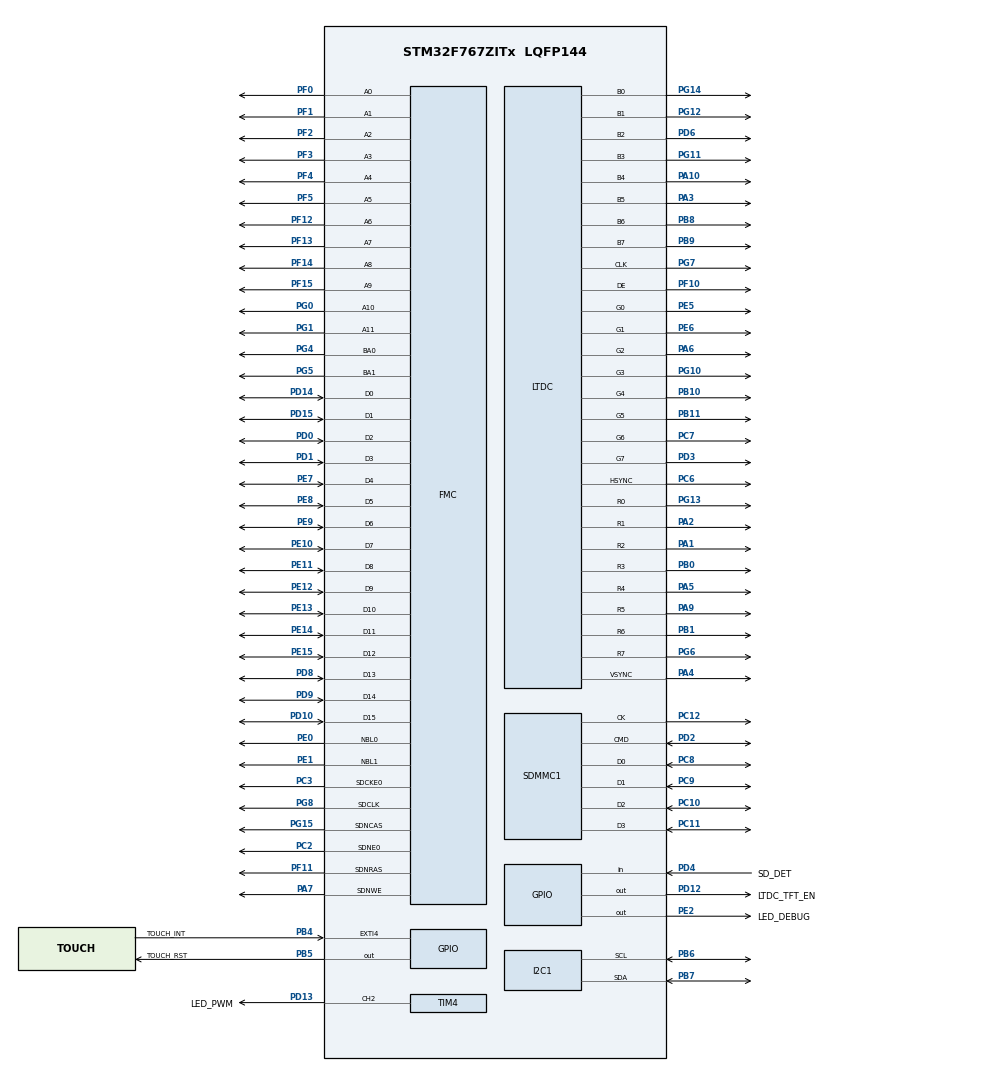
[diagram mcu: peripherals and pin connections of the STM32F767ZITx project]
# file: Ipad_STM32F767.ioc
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CORTEX_M7.CPU_DCache=Enabled
CORTEX_M7.CPU_ICache=Enabled
CORTEX_M7.Cortex_Memory_Protection_Unit_Region1_Settings_S-AccessPermission_S=MPU_REGION_FULL_ACCESS
CORTEX_M7.Cortex_Memory_Protection_Unit_Region1_Settings_S-BaseAddress_S=0xC0000000
CORTEX_M7.Cortex_Memory_Protection_Unit_Region1_Settings_S-DisableExec_S=MPU_INSTRUCTION_ACCESS_DISABLE
CORTEX_M7.Cortex_Memory_Protection_Unit_Region1_Settings_S-Enable_S=MPU_REGION_ENABLE
CORTEX_M7.Cortex_Memory_Protection_Unit_Region1_Settings_S-IsBufferable_S=MPU_ACCESS_BUFFERABLE
CORTEX_M7.Cortex_Memory_Protection_Unit_Region1_Settings_S-IsCacheable_S=MPU_ACCESS_CACHEABLE
CORTEX_M7.Cortex_Memory_Protection_Unit_Region1_Settings_S-IsShareable_S=MPU_ACCESS_NOT_SHAREABLE
CORTEX_M7.Cortex_Memory_Protection_Unit_Region1_Settings_S-Number_Spec=MPU_REGION_NUMBER1
CORTEX_M7.Cortex_Memory_Protection_Unit_Region1_Settings_S-Size_S=MPU_REGION_SIZE_8MB
CORTEX_M7.Cortex_Memory_Protection_Unit_Region1_Settings_S-SubRegionDisable_S=0x0
CORTEX_M7.Cortex_Memory_Protection_Unit_Region1_Settings_S-TypeExtField_S=MPU_TEX_LEVEL1
CORTEX_M7.Cortex_Memory_Protection_Unit_Region2_Settings_S-AccessPermission_S=MPU_REGION_FULL_ACCESS
CORTEX_M7.Cortex_Memory_Protection_Unit_Region2_Settings_S-BaseAddress_S=0xA0000000
CORTEX_M7.Cortex_Memory_Protection_Unit_Region2_Settings_S-DisableExec_S=MPU_INSTRUCTION_ACCESS_DISABLE
CORTEX_M7.Cortex_Memory_Protection_Unit_Region2_Settings_S-Enable_S=MPU_REGION_ENABLE
CORTEX_M7.Cortex_Memory_Protection_Unit_Region2_Settings_S-IsBufferable_S=MPU_ACCESS_BUFFERABLE
CORTEX_M7.Cortex_Memory_Protection_Unit_Region2_Settings_S-IsCacheable_S=MPU_ACCESS_NOT_CACHEABLE
CORTEX_M7.Cortex_Memory_Protection_Unit_Region2_Settings_S-IsShareable_S=MPU_ACCESS_SHAREABLE
CORTEX_M7.Cortex_Memory_Protection_Unit_Region2_Settings_S-Number_Spec=MPU_REGION_NUMBER2
CORTEX_M7.Cortex_Memory_Protection_Unit_Region2_Settings_S-Size_S=MPU_REGION_SIZE_64KB
CORTEX_M7.Cortex_Memory_Protection_Unit_Region2_Settings_S-SubRegionDisable_S=0x0
CORTEX_M7.Cortex_Memory_Protection_Unit_Region2_Settings_S-TypeExtField_S=MPU_TEX_LEVEL0
CORTEX_M7.default_mode_Activation=1
FATFS.BSP.number=1
FATFS._USE_LFN=1
FATFS0.BSP.STBoard=false
FATFS0.BSP.api=Unknown
FATFS0.BSP.instance=PD4
FATFS0.BSP.ip=GPIO
FATFS0.BSP.mode=Input
FATFS0.BSP.name=Detect_SDIO
FATFS0.BSP.solution=PD4
FMC.CASLatency1=FMC_SDRAM_CAS_LATENCY_3
FMC.ColumnBitsNumber1=FMC_SDRAM_COLUMN_BITS_NUM_8
FMC.ExitSelfRefreshDelay1=7
FMC.LoadToActiveDelay1=2
FMC.RCDDelay1=2
FMC.RPDelay1=2
FMC.RPDelay2=2
FMC.ReadBurst1=FMC_SDRAM_RBURST_ENABLE
FMC.ReadPipeDelay1=FMC_SDRAM_RPIPE_DELAY_1
FMC.ReadPipeDelay2=FMC_SDRAM_RPIPE_DELAY_1
FMC.RowCycleDelay1=7
FMC.RowCycleDelay2=7
FMC.SDClockPeriod1=FMC_SDRAM_CLOCK_PERIOD_2
FMC.SDClockPeriod2=FMC_SDRAM_CLOCK_PERIOD_2
FMC.SelfRefreshTime1=4
FMC.WriteRecoveryTime1=3
I2C1.Timing=0x9042161B
LTDC.ActiveH=600
LTDC.ActiveW=1024
LTDC.Alpha_L0=255
LTDC.DEPolarity=LTDC_DEPOLARITY_AL
LTDC.FBStartAdress_L0=0xC0000000
LTDC.HBP=140
LTDC.HFP=160
LTDC.HSPolarity=LTDC_HSPOLARITY_AL
LTDC.HSync=20
LTDC.ImageHeight_L0=600
LTDC.ImageWidth_L0=1024
LTDC.PixelFormat_L0=LTDC_PIXEL_FORMAT_RGB565
LTDC.VBP=20
LTDC.VFP=12
LTDC.VSPolarity=LTDC_VSPOLARITY_AL
LTDC.VSync=3
LTDC.WindowX1_L0=1024
LTDC.WindowY1_L0=600
Mcu.Family=STM32F7
Mcu.Name=STM32F767ZITx
Mcu.Package=LQFP144
NVIC.EXTI4_IRQn=true\:5\:0\:false\:false\:true\:true\:true\:true
NVIC.PriorityGroup=NVIC_PRIORITYGROUP_4
PA1.GPIO_Speed=GPIO_SPEED_FREQ_VERY_HIGH
PA1.Mode=RGB888
PA1.Signal=LTDC_R2
PA10.GPIO_Speed=GPIO_SPEED_FREQ_VERY_HIGH
PA10.Mode=RGB888
PA10.Signal=LTDC_B4
PA13.Mode=Serial_Wire
PA13.Signal=SYS_JTMS-SWDIO
PA14.Mode=Serial_Wire
PA14.Signal=SYS_JTCK-SWCLK
PA2.GPIO_Speed=GPIO_SPEED_FREQ_VERY_HIGH
PA2.Mode=RGB888
PA2.Signal=LTDC_R1
PA3.GPIO_Speed=GPIO_SPEED_FREQ_VERY_HIGH
PA3.Mode=RGB888
PA3.Signal=LTDC_B5
PA4.GPIO_Speed=GPIO_SPEED_FREQ_VERY_HIGH
PA4.Mode=RGB888
PA4.Signal=LTDC_VSYNC
PA5.GPIO_Speed=GPIO_SPEED_FREQ_VERY_HIGH
PA5.Mode=RGB888
PA5.Signal=LTDC_R4
PA6.GPIO_Speed=GPIO_SPEED_FREQ_VERY_HIGH
PA6.Mode=RGB888
PA6.Signal=LTDC_G2
PA7.Signal=FMC_SDNWE
PA9.GPIO_Speed=GPIO_SPEED_FREQ_VERY_HIGH
PA9.Mode=RGB888
PA9.Signal=LTDC_R5
PB0.GPIO_Speed=GPIO_SPEED_FREQ_VERY_HIGH
PB0.Mode=RGB888
PB0.Signal=LTDC_R3
PB1.GPIO_Speed=GPIO_SPEED_FREQ_VERY_HIGH
PB1.Mode=RGB888
PB1.Signal=LTDC_R6
PB10.GPIO_Speed=GPIO_SPEED_FREQ_VERY_HIGH
PB10.Mode=RGB888
PB10.Signal=LTDC_G4
PB11.GPIO_Speed=GPIO_SPEED_FREQ_VERY_HIGH
PB11.Mode=RGB888
PB11.Signal=LTDC_G5
PB4.GPIO_Label=TOUCH_INT
PB4.GPIO_ModeDefaultEXTI=GPIO_MODE_IT_RISING_FALLING
PB4.Signal=GPXTI4
PB5.GPIO_Label=TOUCH_RST
PB5.Signal=GPIO_Output
PB6.GPIO_PuPd=GPIO_PULLUP
PB6.GPIO_Speed=GPIO_SPEED_FREQ_VERY_HIGH
PB6.Mode=I2C
PB6.Signal=I2C1_SCL
PB7.GPIO_PuPd=GPIO_PULLUP
PB7.GPIO_Speed=GPIO_SPEED_FREQ_VERY_HIGH
PB7.Mode=I2C
PB7.Signal=I2C1_SDA
PB8.GPIO_Speed=GPIO_SPEED_FREQ_VERY_HIGH
PB8.Mode=RGB888
PB8.Signal=LTDC_B6
PB9.GPIO_Speed=GPIO_SPEED_FREQ_VERY_HIGH
PB9.Mode=RGB888
PB9.Signal=LTDC_B7
PC10.GPIO_PuPd=GPIO_PULLUP
PC10.GPIO_Speed=GPIO_SPEED_FREQ_VERY_HIGH
PC10.Mode=SD_4_bits_Wide_bus
PC10.Signal=SDMMC1_D2
PC11.GPIO_PuPd=GPIO_PULLUP
PC11.GPIO_Speed=GPIO_SPEED_FREQ_VERY_HIGH
PC11.Mode=SD_4_bits_Wide_bus
PC11.Signal=SDMMC1_D3
PC12.GPIO_Speed=GPIO_SPEED_FREQ_HIGH
PC12.Mode=SD_4_bits_Wide_bus
PC12.Signal=SDMMC1_CK
PC2.Mode=SdramChipSelect1_1
PC2.Signal=FMC_SDNE0
PC3.Mode=SdramChipSelect1_1
PC3.Signal=FMC_SDCKE0
PC6.GPIO_Speed=GPIO_SPEED_FREQ_VERY_HIGH
PC6.Mode=RGB888
PC6.Signal=LTDC_HSYNC
PC7.GPIO_Speed=GPIO_SPEED_FREQ_VERY_HIGH
PC7.Mode=RGB888
PC7.Signal=LTDC_G6
PC8.GPIO_PuPd=GPIO_PULLUP
PC8.GPIO_Speed=GPIO_SPEED_FREQ_VERY_HIGH
PC8.Mode=SD_4_bits_Wide_bus
PC8.Signal=SDMMC1_D0
PC9.GPIO_PuPd=GPIO_PULLUP
PC9.GPIO_Speed=GPIO_SPEED_FREQ_VERY_HIGH
PC9.Mode=SD_4_bits_Wide_bus
PC9.Signal=SDMMC1_D1
PD0.Signal=FMC_D2_DA2
PD1.Signal=FMC_D3_DA3
PD10.Signal=FMC_D15_DA15
PD12.GPIO_Label=LTDC_TFT_EN
PD12.GPIO_PuPd=GPIO_PULLUP
PD12.PinState=GPIO_PIN_SET
PD12.Signal=GPIO_Output
PD13.GPIO_Label=LED_PWM
PD13.Signal=S_TIM4_CH2
PD14.Signal=FMC_D0_DA0
PD15.Signal=FMC_D1_DA1
PD2.GPIO_PuPd=GPIO_PULLUP
PD2.GPIO_Speed=GPIO_SPEED_FREQ_VERY_HIGH
PD2.Mode=SD_4_bits_Wide_bus
PD2.Signal=SDMMC1_CMD
PD3.GPIO_Speed=GPIO_SPEED_FREQ_VERY_HIGH
PD3.Mode=RGB888
PD3.Signal=LTDC_G7
PD4.GPIO_Label=SD_DET
PD4.GPIO_PuPd=GPIO_PULLUP
PD4.Signal=GPIO_Input
PD6.GPIO_Speed=GPIO_SPEED_FREQ_VERY_HIGH
PD6.Mode=RGB888
PD6.Signal=LTDC_B2
PD8.Signal=FMC_D13_DA13
PD9.Signal=FMC_D14_DA14
PE0.Signal=FMC_NBL0
PE1.Signal=FMC_NBL1
PE10.Signal=FMC_D7_DA7
PE11.Signal=FMC_D8_DA8
PE12.Signal=FMC_D9_DA9
PE13.Signal=FMC_D10_DA10
PE14.Signal=FMC_D11_DA11
PE15.Signal=FMC_D12_DA12
PE2.GPIO_Label=LED_DEBUG
PE2.GPIO_PuPd=GPIO_PULLDOWN
PE2.Signal=GPIO_Output
PE5.GPIO_Speed=GPIO_SPEED_FREQ_VERY_HIGH
PE5.Mode=RGB888
PE5.Signal=LTDC_G0
PE6.GPIO_Speed=GPIO_SPEED_FREQ_VERY_HIGH
PE6.Mode=RGB888
PE6.Signal=LTDC_G1
PE7.Signal=FMC_D4_DA4
PE8.Signal=FMC_D5_DA5
PE9.Signal=FMC_D6_DA6
PF0.Signal=FMC_A0
PF1.Signal=FMC_A1
PF10.GPIO_Speed=GPIO_SPEED_FREQ_VERY_HIGH
PF10.Mode=RGB888
PF10.Signal=LTDC_DE
PF11.Signal=FMC_SDNRAS
PF12.Signal=FMC_A6
PF13.Signal=FMC_A7
PF14.Signal=FMC_A8
PF15.Signal=FMC_A9
PF2.Signal=FMC_A2
PF3.Signal=FMC_A3
PF4.Signal=FMC_A4
PF5.Signal=FMC_A5
PG0.Signal=FMC_A10
PG1.Signal=FMC_A11
PG10.GPIO_Speed=GPIO_SPEED_FREQ_VERY_HIGH
PG10.Mode=RGB888
PG10.Signal=LTDC_G3
PG11.GPIO_Speed=GPIO_SPEED_FREQ_VERY_HIGH
PG11.Mode=RGB888
PG11.Signal=LTDC_B3
PG12.GPIO_Speed=GPIO_SPEED_FREQ_VERY_HIGH
PG12.Mode=RGB888
PG12.Signal=LTDC_B1
PG13.GPIO_Speed=GPIO_SPEED_FREQ_VERY_HIGH
PG13.Mode=RGB888
PG13.Signal=LTDC_R0
PG14.GPIO_Speed=GPIO_SPEED_FREQ_VERY_HIGH
PG14.Mode=RGB888
PG14.Signal=LTDC_B0
PG15.Signal=FMC_SDNCAS
PG4.Signal=FMC_A14_BA0
PG5.Signal=FMC_A15_BA1
PG6.GPIO_Speed=GPIO_SPEED_FREQ_VERY_HIGH
PG6.Mode=RGB888
PG6.Signal=LTDC_R7
PG7.GPIO_Speed=GPIO_SPEED_FREQ_VERY_HIGH
PG7.Mode=RGB888
PG7.Signal=LTDC_CLK
PG8.Signal=FMC_SDCLK
PH0/OSC_IN.Mode=HSE-External-Oscillator
PH0/OSC_IN.Signal=RCC_OSC_IN
PH1/OSC_OUT.Mode=HSE-External-Oscillator
PH1/OSC_OUT.Signal=RCC_OSC_OUT
ProjectManager.HeapSize=0x10000
ProjectManager.StackSize=0x2000
ProjectManager.TargetToolchain=STM32CubeIDE
RCC.AHBFreq_Value=200000000
RCC.APB1CLKDivider=RCC_HCLK_DIV4
RCC.APB1Freq_Value=50000000
RCC.APB1TimFreq_Value=100000000
RCC.APB2CLKDivider=RCC_HCLK_DIV2
RCC.APB2Freq_Value=100000000
RCC.APB2TimFreq_Value=200000000
RCC.CortexFreq_Value=200000000
RCC.HCLKFreq_Value=200000000
RCC.HSE_VALUE=25000000
RCC.HSI_VALUE=16000000
RCC.LSE_VALUE=32768
RCC.PLLM=12
RCC.PLLQ=8
RCC.PLLSAIN=172
RCC.PLLSAIRDiv=RCC_PLLSAIDIVR_4
RCC.PLLSourceVirtual=RCC_PLLSOURCE_HSE
RCC.SDMMCClockSelection=RCC_SDMMC1CLKSOURCE_CLK48
RCC.SYSCLKFreq_VALUE=200000000
RCC.SYSCLKSource=RCC_SYSCLKSOURCE_PLLCLK
RCC.USBFreq_Value=50000000
RCC.VCOOutputFreq_Value=400000000
SDMMC1.ClockDiv=0
SH.FMC_A0.0=FMC_A0,12b-sda1
SH.FMC_A1.0=FMC_A1,12b-sda1
SH.FMC_A10.0=FMC_A10,12b-sda1
SH.FMC_A11.0=FMC_A11,12b-sda1
SH.FMC_A14_BA0.0=FMC_BA0,FourSdramBanks1
SH.FMC_A15_BA1.0=FMC_BA1,FourSdramBanks1
SH.FMC_A2.0=FMC_A2,12b-sda1
SH.FMC_A3.0=FMC_A3,12b-sda1
SH.FMC_A4.0=FMC_A4,12b-sda1
SH.FMC_A5.0=FMC_A5,12b-sda1
SH.FMC_A6.0=FMC_A6,12b-sda1
SH.FMC_A7.0=FMC_A7,12b-sda1
SH.FMC_A8.0=FMC_A8,12b-sda1
SH.FMC_A9.0=FMC_A9,12b-sda1
SH.FMC_D0_DA0.0=FMC_D0,sd-16b-d1
SH.FMC_D10_DA10.0=FMC_D10,sd-16b-d1
SH.FMC_D11_DA11.0=FMC_D11,sd-16b-d1
SH.FMC_D12_DA12.0=FMC_D12,sd-16b-d1
SH.FMC_D13_DA13.0=FMC_D13,sd-16b-d1
SH.FMC_D14_DA14.0=FMC_D14,sd-16b-d1
SH.FMC_D15_DA15.0=FMC_D15,sd-16b-d1
SH.FMC_D1_DA1.0=FMC_D1,sd-16b-d1
SH.FMC_D2_DA2.0=FMC_D2,sd-16b-d1
SH.FMC_D3_DA3.0=FMC_D3,sd-16b-d1
SH.FMC_D4_DA4.0=FMC_D4,sd-16b-d1
SH.FMC_D5_DA5.0=FMC_D5,sd-16b-d1
SH.FMC_D6_DA6.0=FMC_D6,sd-16b-d1
SH.FMC_D7_DA7.0=FMC_D7,sd-16b-d1
SH.FMC_D8_DA8.0=FMC_D8,sd-16b-d1
SH.FMC_D9_DA9.0=FMC_D9,sd-16b-d1
SH.FMC_NBL0.0=FMC_NBL0,Sd2ByteEnable1
SH.FMC_NBL1.0=FMC_NBL1,Sd2ByteEnable1
SH.FMC_SDCLK.0=FMC_SDCLK,12b-sda1
SH.FMC_SDNCAS.0=FMC_SDNCAS,12b-sda1
SH.FMC_SDNRAS.0=FMC_SDNRAS,12b-sda1
SH.FMC_SDNWE.0=FMC_SDNWE,12b-sda1
SH.S_TIM4_CH2.0=TIM4_CH2,PWM Generation2 CH2
TIM4.Channel-PWM\ Generation2\ CH2=TIM_CHANNEL_2
TIM4.Period=1999
TIM4.Prescaler=99
TIM4.Pulse-PWM\ Generation2\ CH2=400
VP_DMA2D_VS_DMA2D.Mode=DMA2D_Activate
VP_FATFS_VS_SDIO.Mode=SDIO
VP_JPEG_VS_JPEG.Mode=JPEG_Activate
VP_LIBJPEG_VS_JPEGLIB.Mode=Enabled
board=custom

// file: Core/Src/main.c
/* USER CODE BEGIN Header */
/**
  ******************************************************************************
  * @file           : main.c
  * @brief          : Main program body
  ******************************************************************************
  * @attention
  *
  * Copyright (c) 2026 STMicroelectronics.
  * All rights reserved.
  *
  * This software is licensed under terms that can be found in the LICENSE file
  * in the root directory of this software component.
  * If no LICENSE file comes with this software, it is provided AS-IS.
  *
  ******************************************************************************
  */
/* USER CODE END Header */
#include "main.h"
#include "fatfs.h"
#include "libjpeg.h"

/* USER CODE BEGIN Includes */
#include "periph_test.h"
#include "../../App/App_main.h"

/* USER CODE END Includes */

I2C_HandleTypeDef hi2c1;

LTDC_HandleTypeDef hltdc;

SD_HandleTypeDef hsd1;

SDRAM_HandleTypeDef hsdram1;

void SystemClock_Config(void);
void PeriphCommonClock_Config(void);
static void MPU_Config(void);
static void MX_GPIO_Init(void);
static void MX_TIM4_Init(void);
static void MX_FMC_Init(void);
static void MX_LTDC_Init(void);
static void MX_SDMMC1_SD_Init(void);
static void MX_I2C1_Init(void);

int main(void)
{

  /* MPU Configuration--------------------------------------------------------*/
  MPU_Config();

  /* Enable the CPU Cache */

  /* Enable I-Cache---------------------------------------------------------*/
  SCB_EnableICache();

  /* Enable D-Cache---------------------------------------------------------*/
  SCB_EnableDCache();

  /* MCU Configuration--------------------------------------------------------*/

  /* Reset of all peripherals, Initializes the Flash interface and the Systick. */
  HAL_Init();

  /* Configure the system clock */
  SystemClock_Config();

  /* Configure the peripherals common clocks */
  PeriphCommonClock_Config();

  /* Initialize all configured peripherals */
  MX_GPIO_Init();
  MX_TIM4_Init();
  MX_FMC_Init();
  MX_LTDC_Init();
  MX_SDMMC1_SD_Init();
  MX_I2C1_Init();
  MX_FATFS_Init();
  MX_LIBJPEG_Init();
  /* USER CODE BEGIN 2 */
  Periph_Test_Run();
#if (TEST_SELECT == 0)
  App_Init();
#endif
  /* USER CODE END 2 */

  /* Infinite loop */
  while (1)
  {

    /* USER CODE BEGIN 3 */
#if (TEST_SELECT == 0)
    App_Run();
#endif
  }
  /* USER CODE END 3 */
}

void SystemClock_Config(void)
{
  LL_FLASH_SetLatency(LL_FLASH_LATENCY_6);
  while(LL_FLASH_GetLatency()!= LL_FLASH_LATENCY_6)
  {
  }
  LL_PWR_SetRegulVoltageScaling(LL_PWR_REGU_VOLTAGE_SCALE1);
  LL_PWR_EnableOverDriveMode();
  LL_RCC_HSE_Enable();

   /* Wait till HSE is ready */
  while(LL_RCC_HSE_IsReady() != 1)
  {

  }
  LL_RCC_PLL_ConfigDomain_SYS(LL_RCC_PLLSOURCE_HSE, LL_RCC_PLLM_DIV_12, 192, LL_RCC_PLLP_DIV_2);
  LL_RCC_PLL_ConfigDomain_48M(LL_RCC_PLLSOURCE_HSE, LL_RCC_PLLM_DIV_12, 192, LL_RCC_PLLQ_DIV_8);
  LL_RCC_PLL_Enable();

   /* Wait till PLL is ready */
  while(LL_RCC_PLL_IsReady() != 1)
  {

  }
  while (LL_PWR_IsActiveFlag_VOS() == 0)
  {
  }
  LL_RCC_SetAHBPrescaler(LL_RCC_SYSCLK_DIV_1);
  LL_RCC_SetAPB1Prescaler(LL_RCC_APB1_DIV_4);
  LL_RCC_SetAPB2Prescaler(LL_RCC_APB2_DIV_2);
  LL_RCC_SetSysClkSource(LL_RCC_SYS_CLKSOURCE_PLL);

   /* Wait till System clock is ready */
  while(LL_RCC_GetSysClkSource() != LL_RCC_SYS_CLKSOURCE_STATUS_PLL)
  {

  }
  LL_SetSystemCoreClock(200000000);

   /* Update the time base */
  if (HAL_InitTick (TICK_INT_PRIORITY) != HAL_OK)
  {
    Error_Handler();
  }

   /* Set Timers Clock Prescalers */
  LL_RCC_SetTIMPrescaler(LL_RCC_TIM_PRESCALER_TWICE);
}

void PeriphCommonClock_Config(void)
{
  LL_RCC_PLLSAI_ConfigDomain_LTDC(LL_RCC_PLLSOURCE_HSE, LL_RCC_PLLM_DIV_12, 172, LL_RCC_PLLSAIR_DIV_2, LL_RCC_PLLSAIDIVR_DIV_4);
  LL_RCC_PLLSAI_Enable();

   /* Wait till PLL is ready */
  while(LL_RCC_PLLSAI_IsReady() != 1)
  {

  }
}

static void MX_I2C1_Init(void)
{

  hi2c1.Instance = I2C1;
  hi2c1.Init.Timing = 0x9042161B;
  hi2c1.Init.OwnAddress1 = 0;
  hi2c1.Init.AddressingMode = I2C_ADDRESSINGMODE_7BIT;
  hi2c1.Init.DualAddressMode = I2C_DUALADDRESS_DISABLE;
  hi2c1.Init.OwnAddress2 = 0;
  hi2c1.Init.OwnAddress2Masks = I2C_OA2_NOMASK;
  hi2c1.Init.GeneralCallMode = I2C_GENERALCALL_DISABLE;
  hi2c1.Init.NoStretchMode = I2C_NOSTRETCH_DISABLE;
  if (HAL_I2C_Init(&hi2c1) != HAL_OK)
  {
    Error_Handler();
  }

  /** Configure Analogue filter
  */
  if (HAL_I2CEx_ConfigAnalogFilter(&hi2c1, I2C_ANALOGFILTER_ENABLE) != HAL_OK)
  {
    Error_Handler();
  }

  /** Configure Digital filter
  */
  if (HAL_I2CEx_ConfigDigitalFilter(&hi2c1, 0) != HAL_OK)
  {
    Error_Handler();
  }

}

static void MX_LTDC_Init(void)
{

  LTDC_LayerCfgTypeDef pLayerCfg = {0};
  LTDC_LayerCfgTypeDef pLayerCfg1 = {0};

  hltdc.Instance = LTDC;
  hltdc.Init.HSPolarity = LTDC_HSPOLARITY_AL;
  hltdc.Init.VSPolarity = LTDC_VSPOLARITY_AL;
  hltdc.Init.DEPolarity = LTDC_DEPOLARITY_AL;
  hltdc.Init.PCPolarity = LTDC_PCPOLARITY_IPC;
  hltdc.Init.HorizontalSync = 19;
  hltdc.Init.VerticalSync = 2;
  hltdc.Init.AccumulatedHBP = 159;
  hltdc.Init.AccumulatedVBP = 22;
  hltdc.Init.AccumulatedActiveW = 1183;
  hltdc.Init.AccumulatedActiveH = 622;
  hltdc.Init.TotalWidth = 1343;
  hltdc.Init.TotalHeigh = 634;
  hltdc.Init.Backcolor.Blue = 0;
  hltdc.Init.Backcolor.Green = 0;
  hltdc.Init.Backcolor.Red = 0;
  if (HAL_LTDC_Init(&hltdc) != HAL_OK)
  {
    Error_Handler();
  }
  pLayerCfg.WindowX0 = 0;
  pLayerCfg.WindowX1 = 1024;
  pLayerCfg.WindowY0 = 0;
  pLayerCfg.WindowY1 = 600;
  pLayerCfg.PixelFormat = LTDC_PIXEL_FORMAT_RGB565;
  pLayerCfg.Alpha = 255;
  pLayerCfg.Alpha0 = 0;
  pLayerCfg.BlendingFactor1 = LTDC_BLENDING_FACTOR1_CA;
  pLayerCfg.BlendingFactor2 = LTDC_BLENDING_FACTOR2_CA;
  pLayerCfg.FBStartAdress = 0xC0000000;
  pLayerCfg.ImageWidth = 1024;
  pLayerCfg.ImageHeight = 600;
  pLayerCfg.Backcolor.Blue = 0;
  pLayerCfg.Backcolor.Green = 0;
  pLayerCfg.Backcolor.Red = 0;
  if (HAL_LTDC_ConfigLayer(&hltdc, &pLayerCfg, 0) != HAL_OK)
  {
    Error_Handler();
  }
  pLayerCfg1.WindowX0 = 0;
  pLayerCfg1.WindowX1 = 0;
  pLayerCfg1.WindowY0 = 0;
  pLayerCfg1.WindowY1 = 0;
  pLayerCfg1.PixelFormat = LTDC_PIXEL_FORMAT_ARGB8888;
  pLayerCfg1.Alpha = 0;
  pLayerCfg1.Alpha0 = 0;
  pLayerCfg1.BlendingFactor1 = LTDC_BLENDING_FACTOR1_CA;
  pLayerCfg1.BlendingFactor2 = LTDC_BLENDING_FACTOR2_CA;
  pLayerCfg1.FBStartAdress = 0;
  pLayerCfg1.ImageWidth = 0;
  pLayerCfg1.ImageHeight = 0;
  pLayerCfg1.Backcolor.Blue = 0;
  pLayerCfg1.Backcolor.Green = 0;
  pLayerCfg1.Backcolor.Red = 0;
  if (HAL_LTDC_ConfigLayer(&hltdc, &pLayerCfg1, 1) != HAL_OK)
  {
    Error_Handler();
  }

}

static void MX_SDMMC1_SD_Init(void)
{

  hsd1.Instance = SDMMC1;
  hsd1.Init.ClockEdge = SDMMC_CLOCK_EDGE_RISING;
  hsd1.Init.ClockBypass = SDMMC_CLOCK_BYPASS_DISABLE;
  hsd1.Init.ClockPowerSave = SDMMC_CLOCK_POWER_SAVE_DISABLE;
  hsd1.Init.BusWide = SDMMC_BUS_WIDE_1B;
  hsd1.Init.HardwareFlowControl = SDMMC_HARDWARE_FLOW_CONTROL_DISABLE;
  hsd1.Init.ClockDiv = 0;

}

static void MX_TIM4_Init(void)
{

  LL_TIM_InitTypeDef TIM_InitStruct = {0};
  LL_TIM_OC_InitTypeDef TIM_OC_InitStruct = {0};

  LL_GPIO_InitTypeDef GPIO_InitStruct = {0};

  /* Peripheral clock enable */
  LL_APB1_GRP1_EnableClock(LL_APB1_GRP1_PERIPH_TIM4);

  TIM_InitStruct.Prescaler = 99;
  TIM_InitStruct.CounterMode = LL_TIM_COUNTERMODE_UP;
  TIM_InitStruct.Autoreload = 1999;
  TIM_InitStruct.ClockDivision = LL_TIM_CLOCKDIVISION_DIV1;
  LL_TIM_Init(TIM4, &TIM_InitStruct);
  LL_TIM_DisableARRPreload(TIM4);
  LL_TIM_OC_EnablePreload(TIM4, LL_TIM_CHANNEL_CH2);
  TIM_OC_InitStruct.OCMode = LL_TIM_OCMODE_PWM1;
  TIM_OC_InitStruct.OCState = LL_TIM_OCSTATE_DISABLE;
  TIM_OC_InitStruct.OCNState = LL_TIM_OCSTATE_DISABLE;
  TIM_OC_InitStruct.CompareValue = 400;
  TIM_OC_InitStruct.OCPolarity = LL_TIM_OCPOLARITY_HIGH;
  LL_TIM_OC_Init(TIM4, LL_TIM_CHANNEL_CH2, &TIM_OC_InitStruct);
  LL_TIM_OC_DisableFast(TIM4, LL_TIM_CHANNEL_CH2);
  LL_TIM_SetTriggerOutput(TIM4, LL_TIM_TRGO_RESET);
  LL_TIM_DisableMasterSlaveMode(TIM4);
  LL_AHB1_GRP1_EnableClock(LL_AHB1_GRP1_PERIPH_GPIOD);
  /**TIM4 GPIO Configuration
  PD13   ------> TIM4_CH2
  */
  GPIO_InitStruct.Pin = LED_PWM_Pin;
  GPIO_InitStruct.Mode = LL_GPIO_MODE_ALTERNATE;
  GPIO_InitStruct.Speed = LL_GPIO_SPEED_FREQ_LOW;
  GPIO_InitStruct.OutputType = LL_GPIO_OUTPUT_PUSHPULL;
  GPIO_InitStruct.Pull = LL_GPIO_PULL_NO;
  GPIO_InitStruct.Alternate = LL_GPIO_AF_2;
  LL_GPIO_Init(LED_PWM_GPIO_Port, &GPIO_InitStruct);

}

/* FMC initialization function */
static void MX_FMC_Init(void)
{

  FMC_SDRAM_TimingTypeDef SdramTiming = {0};

  /** Perform the SDRAM1 memory initialization sequence
  */
  hsdram1.Instance = FMC_SDRAM_DEVICE;
  /* hsdram1.Init */
  hsdram1.Init.SDBank = FMC_SDRAM_BANK1;
  hsdram1.Init.ColumnBitsNumber = FMC_SDRAM_COLUMN_BITS_NUM_8;
  hsdram1.Init.RowBitsNumber = FMC_SDRAM_ROW_BITS_NUM_12;
  hsdram1.Init.MemoryDataWidth = FMC_SDRAM_MEM_BUS_WIDTH_16;
  hsdram1.Init.InternalBankNumber = FMC_SDRAM_INTERN_BANKS_NUM_4;
  hsdram1.Init.CASLatency = FMC_SDRAM_CAS_LATENCY_3;
  hsdram1.Init.WriteProtection = FMC_SDRAM_WRITE_PROTECTION_DISABLE;
  hsdram1.Init.SDClockPeriod = FMC_SDRAM_CLOCK_PERIOD_2;
  hsdram1.Init.ReadBurst = FMC_SDRAM_RBURST_ENABLE;
  hsdram1.Init.ReadPipeDelay = FMC_SDRAM_RPIPE_DELAY_1;
  /* SdramTiming */
  SdramTiming.LoadToActiveDelay = 2;
  SdramTiming.ExitSelfRefreshDelay = 7;
  SdramTiming.SelfRefreshTime = 4;
  SdramTiming.RowCycleDelay = 7;
  SdramTiming.WriteRecoveryTime = 3;
  SdramTiming.RPDelay = 2;
  SdramTiming.RCDDelay = 2;

  if (HAL_SDRAM_Init(&hsdram1, &SdramTiming) != HAL_OK)
  {
    Error_Handler( );
  }

}

static void MX_GPIO_Init(void)
{
  LL_EXTI_InitTypeDef EXTI_InitStruct = {0};
  LL_GPIO_InitTypeDef GPIO_InitStruct = {0};

  /* GPIO Ports Clock Enable */
  LL_AHB1_GRP1_EnableClock(LL_AHB1_GRP1_PERIPH_GPIOE);
  LL_AHB1_GRP1_EnableClock(LL_AHB1_GRP1_PERIPH_GPIOF);
  LL_AHB1_GRP1_EnableClock(LL_AHB1_GRP1_PERIPH_GPIOH);
  LL_AHB1_GRP1_EnableClock(LL_AHB1_GRP1_PERIPH_GPIOC);
  LL_AHB1_GRP1_EnableClock(LL_AHB1_GRP1_PERIPH_GPIOA);
  LL_AHB1_GRP1_EnableClock(LL_AHB1_GRP1_PERIPH_GPIOB);
  LL_AHB1_GRP1_EnableClock(LL_AHB1_GRP1_PERIPH_GPIOG);
  LL_AHB1_GRP1_EnableClock(LL_AHB1_GRP1_PERIPH_GPIOD);

  /**/
  LL_GPIO_ResetOutputPin(LED_DEBUG_GPIO_Port, LED_DEBUG_Pin);

  /**/
  LL_GPIO_SetOutputPin(LTDC_TFT_EN_GPIO_Port, LTDC_TFT_EN_Pin);

  /**/
  LL_GPIO_ResetOutputPin(TOUCH_RST_GPIO_Port, TOUCH_RST_Pin);

  /**/
  GPIO_InitStruct.Pin = LED_DEBUG_Pin;
  GPIO_InitStruct.Mode = LL_GPIO_MODE_OUTPUT;
  GPIO_InitStruct.Speed = LL_GPIO_SPEED_FREQ_LOW;
  GPIO_InitStruct.OutputType = LL_GPIO_OUTPUT_PUSHPULL;
  GPIO_InitStruct.Pull = LL_GPIO_PULL_DOWN;
  LL_GPIO_Init(LED_DEBUG_GPIO_Port, &GPIO_InitStruct);

  /**/
  GPIO_InitStruct.Pin = LTDC_TFT_EN_Pin;
  GPIO_InitStruct.Mode = LL_GPIO_MODE_OUTPUT;
  GPIO_InitStruct.Speed = LL_GPIO_SPEED_FREQ_LOW;
  GPIO_InitStruct.OutputType = LL_GPIO_OUTPUT_PUSHPULL;
  GPIO_InitStruct.Pull = LL_GPIO_PULL_UP;
  LL_GPIO_Init(LTDC_TFT_EN_GPIO_Port, &GPIO_InitStruct);

  /**/
  GPIO_InitStruct.Pin = SD_DET_Pin;
  GPIO_InitStruct.Mode = LL_GPIO_MODE_INPUT;
  GPIO_InitStruct.Pull = LL_GPIO_PULL_UP;
  LL_GPIO_Init(SD_DET_GPIO_Port, &GPIO_InitStruct);

  /**/
  GPIO_InitStruct.Pin = TOUCH_RST_Pin;
  GPIO_InitStruct.Mode = LL_GPIO_MODE_OUTPUT;
  GPIO_InitStruct.Speed = LL_GPIO_SPEED_FREQ_LOW;
  GPIO_InitStruct.OutputType = LL_GPIO_OUTPUT_PUSHPULL;
  GPIO_InitStruct.Pull = LL_GPIO_PULL_NO;
  LL_GPIO_Init(TOUCH_RST_GPIO_Port, &GPIO_InitStruct);

  /**/
  LL_SYSCFG_SetEXTISource(LL_SYSCFG_EXTI_PORTB, LL_SYSCFG_EXTI_LINE4);

  /**/
  EXTI_InitStruct.Line_0_31 = LL_EXTI_LINE_4;
  EXTI_InitStruct.LineCommand = ENABLE;
  EXTI_InitStruct.Mode = LL_EXTI_MODE_IT;
  EXTI_InitStruct.Trigger = LL_EXTI_TRIGGER_RISING_FALLING;
  LL_EXTI_Init(&EXTI_InitStruct);

  /**/
  LL_GPIO_SetPinPull(TOUCH_INT_GPIO_Port, TOUCH_INT_Pin, LL_GPIO_PULL_NO);

  /**/
  LL_GPIO_SetPinMode(TOUCH_INT_GPIO_Port, TOUCH_INT_Pin, LL_GPIO_MODE_INPUT);

  /* EXTI interrupt init*/
  NVIC_SetPriority(EXTI4_IRQn, NVIC_EncodePriority(NVIC_GetPriorityGrouping(),5, 0));
  NVIC_EnableIRQ(EXTI4_IRQn);

}

 /* MPU Configuration */

void MPU_Config(void)
{

  /* Disables the MPU */
  LL_MPU_Disable();

  /** Initializes and configures the Region and the memory to be protected
  */
  LL_MPU_ConfigRegion(LL_MPU_REGION_NUMBER0, 0x87, 0x0, LL_MPU_REGION_SIZE_4GB|LL_MPU_TEX_LEVEL0|LL_MPU_REGION_NO_ACCESS|LL_MPU_INSTRUCTION_ACCESS_DISABLE|LL_MPU_ACCESS_SHAREABLE|LL_MPU_ACCESS_NOT_CACHEABLE|LL_MPU_ACCESS_NOT_BUFFERABLE);
  /* Enables the MPU */
  LL_MPU_Enable(LL_MPU_CTRL_PRIVILEGED_DEFAULT);

}

void Error_Handler(void)
{
  /* USER CODE BEGIN Error_Handler_Debug */
  /* User can add his own implementation to report the HAL error return state */
  __disable_irq();
  /* Màn hình CAM = Error_Handler (tắt layer, đổi màu nền LTDC, không cần SDRAM) */
  LTDC_Layer1->CR &= ~LTDC_LxCR_LEN;
  LTDC_Layer2->CR &= ~LTDC_LxCR_LEN;
  LTDC->BCCR = 0x00FF8000UL;
  LTDC->SRCR = LTDC_SRCR_IMR;
  while (1)
  {
    /* Nháy nhanh LED_DEBUG: báo lỗi khởi tạo */
    LL_GPIO_TogglePin(LED_DEBUG_GPIO_Port, LED_DEBUG_Pin);
    for (volatile uint32_t d = 0; d < 300000U; d++) { }
  }
  /* USER CODE END Error_Handler_Debug */
}
